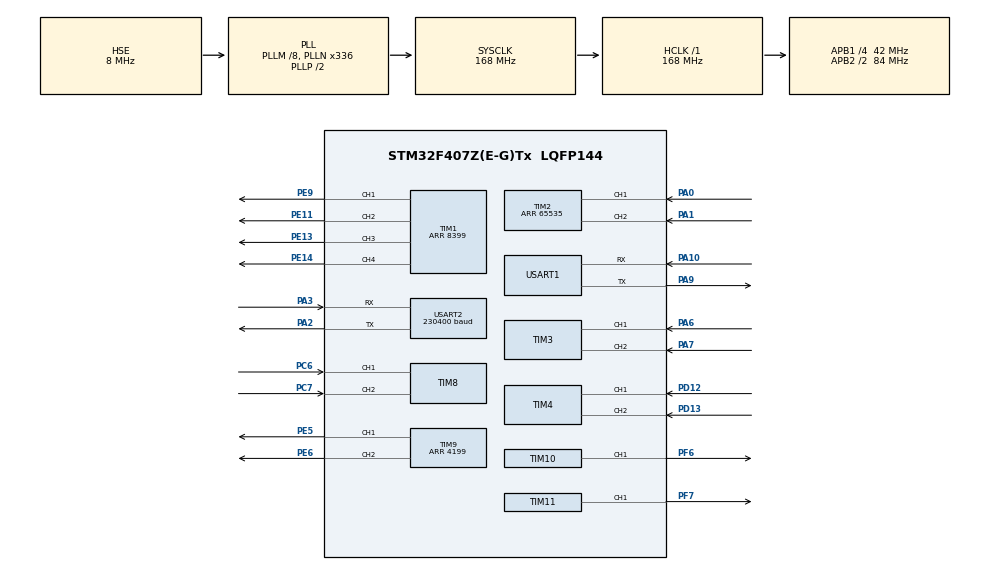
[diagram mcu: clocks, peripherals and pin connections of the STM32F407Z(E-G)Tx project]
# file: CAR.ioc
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FREERTOS.Tasks01=defaultTask,24,128,StartDefaultTask,Default,NULL,Dynamic,NULL,NULL;TaskControl,48,256,StartTaskControl,Default,NULL,Dynamic,NULL,NULL;TaskComm,32,256,StartTaskComm,Default,NULL,Dynamic,NULL,NULL;TaskReport,24,128,StartTaskReport,Default,NULL,Dynamic,NULL,NULL
Mcu.Family=STM32F4
Mcu.Name=STM32F407Z(E-G)Tx
Mcu.Package=LQFP144
NVIC.PriorityGroup=NVIC_PRIORITYGROUP_4
NVIC.TIM7_IRQn=true\:15\:0\:false\:false\:true\:false\:false\:true\:true
NVIC.TimeBase=TIM7_IRQn
NVIC.TimeBaseIP=TIM7
NVIC.USART1_IRQn=true\:5\:0\:false\:false\:true\:true\:true\:true\:true
NVIC.USART2_IRQn=true\:5\:0\:false\:false\:true\:true\:true\:true\:true
PA0-WKUP.GPIO_PuPd=GPIO_PULLUP
PA0-WKUP.Signal=S_TIM2_CH1_ETR
PA1.GPIO_PuPd=GPIO_PULLUP
PA1.Signal=S_TIM2_CH2
PA10.GPIO_PuPd=GPIO_PULLUP
PA10.Mode=Asynchronous
PA10.Signal=USART1_RX
PA13.Mode=Serial_Wire
PA13.Signal=SYS_JTMS-SWDIO
PA14.Mode=Serial_Wire
PA14.Signal=SYS_JTCK-SWCLK
PA2.Mode=Asynchronous
PA2.Signal=USART2_TX
PA3.GPIO_PuPd=GPIO_PULLUP
PA3.Mode=Asynchronous
PA3.Signal=USART2_RX
PA6.GPIO_PuPd=GPIO_PULLUP
PA6.Signal=S_TIM3_CH1
PA7.GPIO_PuPd=GPIO_PULLUP
PA7.Signal=S_TIM3_CH2
PA9.Mode=Asynchronous
PA9.Signal=USART1_TX
PC6.GPIO_PuPd=GPIO_PULLUP
PC6.Signal=S_TIM8_CH1
PC7.GPIO_PuPd=GPIO_PULLUP
PC7.Signal=S_TIM8_CH2
PD12.GPIO_PuPd=GPIO_PULLUP
PD12.Signal=S_TIM4_CH1
PD13.GPIO_PuPd=GPIO_PULLUP
PD13.Signal=S_TIM4_CH2
PE11.Signal=S_TIM1_CH2
PE13.Signal=S_TIM1_CH3
PE14.Signal=S_TIM1_CH4
PE5.Signal=S_TIM9_CH1
PE6.Signal=S_TIM9_CH2
PE9.Signal=S_TIM1_CH1
PF6.Signal=S_TIM10_CH1
PF7.Signal=S_TIM11_CH1
PH0-OSC_IN.Mode=HSE-External-Oscillator
PH0-OSC_IN.Signal=RCC_OSC_IN
PH1-OSC_OUT.Mode=HSE-External-Oscillator
PH1-OSC_OUT.Signal=RCC_OSC_OUT
ProjectManager.HeapSize=0x200
ProjectManager.StackSize=0x400
ProjectManager.TargetToolchain=MDK-ARM V5
RCC.48MHZClocksFreq_Value=84000000
RCC.AHBFreq_Value=168000000
RCC.APB1CLKDivider=RCC_HCLK_DIV4
RCC.APB1Freq_Value=42000000
RCC.APB1TimFreq_Value=84000000
RCC.APB2CLKDivider=RCC_HCLK_DIV2
RCC.APB2Freq_Value=84000000
RCC.APB2TimFreq_Value=168000000
RCC.CortexFreq_Value=168000000
RCC.HCLKFreq_Value=168000000
RCC.HSE_VALUE=8000000
RCC.HSI_VALUE=16000000
RCC.LSE_VALUE=32768
RCC.PLLM=8
RCC.PLLN=336
RCC.PLLSourceVirtual=RCC_PLLSOURCE_HSE
RCC.SYSCLKFreq_VALUE=168000000
RCC.SYSCLKSource=RCC_SYSCLKSOURCE_PLLCLK
RCC.VCOOutputFreq_Value=336000000
SH.S_TIM10_CH1.0=TIM10_CH1,Output Compare1 CH1
SH.S_TIM11_CH1.0=TIM11_CH1,PWM Generation1 CH1
SH.S_TIM1_CH1.0=TIM1_CH1,PWM Generation1 CH1
SH.S_TIM1_CH2.0=TIM1_CH2,PWM Generation2 CH2
SH.S_TIM1_CH3.0=TIM1_CH3,PWM Generation3 CH3
SH.S_TIM1_CH4.0=TIM1_CH4,PWM Generation4 CH4
SH.S_TIM2_CH1_ETR.0=TIM2_CH1,Encoder_Interface
SH.S_TIM2_CH2.0=TIM2_CH2,Encoder_Interface
SH.S_TIM3_CH1.0=TIM3_CH1,Encoder_Interface
SH.S_TIM3_CH2.0=TIM3_CH2,Encoder_Interface
SH.S_TIM4_CH1.0=TIM4_CH1,Encoder_Interface
SH.S_TIM4_CH2.0=TIM4_CH2,Encoder_Interface
SH.S_TIM8_CH1.0=TIM8_CH1,Encoder_Interface
SH.S_TIM8_CH2.0=TIM8_CH2,Encoder_Interface
SH.S_TIM9_CH1.0=TIM9_CH1,PWM Generation1 CH1
SH.S_TIM9_CH2.0=TIM9_CH2,PWM Generation2 CH2
TIM1.AutoReloadPreload=TIM_AUTORELOAD_PRELOAD_ENABLE
TIM1.Channel-PWM\ Generation1\ CH1=TIM_CHANNEL_1
TIM1.Channel-PWM\ Generation2\ CH2=TIM_CHANNEL_2
TIM1.Channel-PWM\ Generation3\ CH3=TIM_CHANNEL_3
TIM1.Channel-PWM\ Generation4\ CH4=TIM_CHANNEL_4
TIM1.Period=8399
TIM10.AutoReloadPreload=TIM_AUTORELOAD_PRELOAD_ENABLE
TIM10.Channel=TIM_CHANNEL_1
TIM10.Period=4199
TIM11.AutoReloadPreload=TIM_AUTORELOAD_PRELOAD_ENABLE
TIM11.Channel=TIM_CHANNEL_1
TIM11.Period=4199
TIM2.EncoderMode=TIM_ENCODERMODE_TI12
TIM2.IC1Filter=6
TIM2.IC2Filter=6
TIM2.Period=65535
TIM3.EncoderMode=TIM_ENCODERMODE_TI12
TIM3.IC1Filter=6
TIM3.IC2Filter=6
TIM4.EncoderMode=TIM_ENCODERMODE_TI12
TIM4.IC1Filter=6
TIM4.IC2Filter=6
TIM8.EncoderMode=TIM_ENCODERMODE_TI12
TIM8.IC1Filter=6
TIM8.IC2Filter=6
TIM9.AutoReloadPreload=TIM_AUTORELOAD_PRELOAD_ENABLE
TIM9.Channel-PWM\ Generation1\ CH1=TIM_CHANNEL_1
TIM9.Channel-PWM\ Generation2\ CH2=TIM_CHANNEL_2
TIM9.Period=4199
USART1.VirtualMode=VM_ASYNC
USART2.BaudRate=230400
USART2.VirtualMode=VM_ASYNC
VP_FREERTOS_VS_CMSIS_V2.Mode=CMSIS_V2
VP_SYS_VS_tim7.Mode=TIM7
VP_TIM10_VS_ClockSourceINT.Mode=Enable_Timer
VP_TIM11_VS_ClockSourceINT.Mode=Enable_Timer
board=custom

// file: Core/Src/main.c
/* USER CODE BEGIN Header */
/**
  ******************************************************************************
  * @file           : main.c
  * @brief          : Main program body
  ******************************************************************************
  * @attention
  *
  * Copyright (c) 2026 STMicroelectronics.
  * All rights reserved.
  *
  * This software is licensed under terms that can be found in the LICENSE file
  * in the root directory of this software component.
  * If no LICENSE file comes with this software, it is provided AS-IS.
  *
  ******************************************************************************
  */
/* USER CODE END Header */
#include "main.h"
#include "cmsis_os.h"
#include "tim.h"
#include "usart.h"
#include "gpio.h"

void SystemClock_Config(void);
void MX_FREERTOS_Init(void);

int main(void)
{

  /* MCU Configuration--------------------------------------------------------*/

  /* Reset of all peripherals, Initializes the Flash interface and the Systick. */
  HAL_Init();

  /* Configure the system clock */
  SystemClock_Config();

  /* Initialize all configured peripherals */
  MX_GPIO_Init();
  MX_TIM1_Init();
  MX_TIM2_Init();
  MX_TIM3_Init();
  MX_TIM4_Init();
  MX_TIM8_Init();
  MX_TIM9_Init();
  MX_TIM10_Init();
  MX_TIM11_Init();
  MX_USART1_UART_Init();
  MX_USART2_UART_Init();

  /* Init scheduler */
  osKernelInitialize();  /* Call init function for freertos objects (in cmsis_os2.c) */
  MX_FREERTOS_Init();

  /* Start scheduler */
  osKernelStart();

  /* We should never get here as control is now taken by the scheduler */

  /* Infinite loop */
  while (1)
  {

  }
}

void SystemClock_Config(void)
{
  RCC_OscInitTypeDef RCC_OscInitStruct = {0};
  RCC_ClkInitTypeDef RCC_ClkInitStruct = {0};

  /** Configure the main internal regulator output voltage
  */
  __HAL_RCC_PWR_CLK_ENABLE();
  __HAL_PWR_VOLTAGESCALING_CONFIG(PWR_REGULATOR_VOLTAGE_SCALE1);

  /** Initializes the RCC Oscillators according to the specified parameters
  * in the RCC_OscInitTypeDef structure.
  */
  RCC_OscInitStruct.OscillatorType = RCC_OSCILLATORTYPE_HSE;
  RCC_OscInitStruct.HSEState = RCC_HSE_ON;
  RCC_OscInitStruct.PLL.PLLState = RCC_PLL_ON;
  RCC_OscInitStruct.PLL.PLLSource = RCC_PLLSOURCE_HSE;
  RCC_OscInitStruct.PLL.PLLM = 8;
  RCC_OscInitStruct.PLL.PLLN = 336;
  RCC_OscInitStruct.PLL.PLLP = RCC_PLLP_DIV2;
  RCC_OscInitStruct.PLL.PLLQ = 4;
  if (HAL_RCC_OscConfig(&RCC_OscInitStruct) != HAL_OK)
  {
    Error_Handler();
  }

  /** Initializes the CPU, AHB and APB buses clocks
  */
  RCC_ClkInitStruct.ClockType = RCC_CLOCKTYPE_HCLK|RCC_CLOCKTYPE_SYSCLK
                              |RCC_CLOCKTYPE_PCLK1|RCC_CLOCKTYPE_PCLK2;
  RCC_ClkInitStruct.SYSCLKSource = RCC_SYSCLKSOURCE_PLLCLK;
  RCC_ClkInitStruct.AHBCLKDivider = RCC_SYSCLK_DIV1;
  RCC_ClkInitStruct.APB1CLKDivider = RCC_HCLK_DIV4;
  RCC_ClkInitStruct.APB2CLKDivider = RCC_HCLK_DIV2;

  if (HAL_RCC_ClockConfig(&RCC_ClkInitStruct, FLASH_LATENCY_5) != HAL_OK)
  {
    Error_Handler();
  }
}

void HAL_TIM_PeriodElapsedCallback(TIM_HandleTypeDef *htim)
{
  if (htim->Instance == TIM7)
  {
    HAL_IncTick();
  }
}

void Error_Handler(void)
{
  __disable_irq();
  while (1)
  {
  }
}

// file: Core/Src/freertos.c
/* USER CODE BEGIN Header */
/**
  ******************************************************************************
  * File Name          : freertos.c
  * Description        : Code for freertos applications
  ******************************************************************************
  * @attention
  *
  * Copyright (c) 2026 STMicroelectronics.
  * All rights reserved.
  *
  * This software is licensed under terms that can be found in the LICENSE file
  * in the root directory of this software component.
  * If no LICENSE file comes with this software, it is provided AS-IS.
  *
  ******************************************************************************
  */
/* USER CODE END Header */

#include "FreeRTOS.h"
#include "task.h"
#include "main.h"
#include "cmsis_os.h"

/* USER CODE BEGIN Includes */
#include "chassis.h"
#include "motor.h"
#include "electromotor.h"
#include "board.h"
#include "board_Protocol.h"
#include "control_task.h"
#include "board_task.h"
/* USER CODE END Includes */

/* Definitions for defaultTask */
osThreadId_t defaultTaskHandle;
const osThreadAttr_t defaultTask_attributes = {
  .name = "defaultTask",
  .stack_size = 128 * 4,
  .priority = (osPriority_t) osPriorityNormal,
};
/* Definitions for TaskControl */
osThreadId_t TaskControlHandle;
const osThreadAttr_t TaskControl_attributes = {
  .name = "TaskControl",
  .stack_size = 256 * 4,
  .priority = (osPriority_t) osPriorityRealtime,
};
/* Definitions for TaskComm */
osThreadId_t TaskCommHandle;
const osThreadAttr_t TaskComm_attributes = {
  .name = "TaskComm",
  .stack_size = 256 * 4,
  .priority = (osPriority_t) osPriorityAboveNormal,
};
/* Definitions for TaskReport */
osThreadId_t TaskReportHandle;
const osThreadAttr_t TaskReport_attributes = {
  .name = "TaskReport",
  .stack_size = 128 * 4,
  .priority = (osPriority_t) osPriorityNormal,
};

void StartDefaultTask(void *argument);
void StartTaskControl(void *argument);
void StartTaskComm(void *argument);
void StartTaskReport(void *argument);

void MX_FREERTOS_Init(void); /* (MISRA C 2004 rule 8.1) */

void MX_FREERTOS_Init(void) {
  /* USER CODE BEGIN Init */
  EM_Init();
  Motor_Init();
  Chassis_Init();
  Board_Init();
  /* USER CODE END Init */

  /* Create the thread(s) */
  /* creation of defaultTask */
  defaultTaskHandle = osThreadNew(StartDefaultTask, NULL, &defaultTask_attributes);

  /* creation of TaskControl */
  TaskControlHandle = osThreadNew(StartTaskControl, NULL, &TaskControl_attributes);

  /* creation of TaskComm */
  TaskCommHandle = osThreadNew(StartTaskComm, NULL, &TaskComm_attributes);

  /* creation of TaskReport */
  TaskReportHandle = osThreadNew(StartTaskReport, NULL, &TaskReport_attributes);

}

void StartDefaultTask(void *argument)
{
  for(;;)
  {
    osDelay(1);
  }
}

void StartTaskControl(void *argument)
{
  /* USER CODE BEGIN StartTaskControl */
  Task_Control();
  /* USER CODE END StartTaskControl */
}

void StartTaskComm(void *argument)
{
  /* USER CODE BEGIN StartTaskComm */
  /* Infinite loop */
  for(;;)
  {
    osDelay(10);
  }
  /* USER CODE END StartTaskComm */
}

void StartTaskReport(void *argument)
{
  /* USER CODE BEGIN StartTaskReport */
  Task_Board();
  /* USER CODE END StartTaskReport */
}
